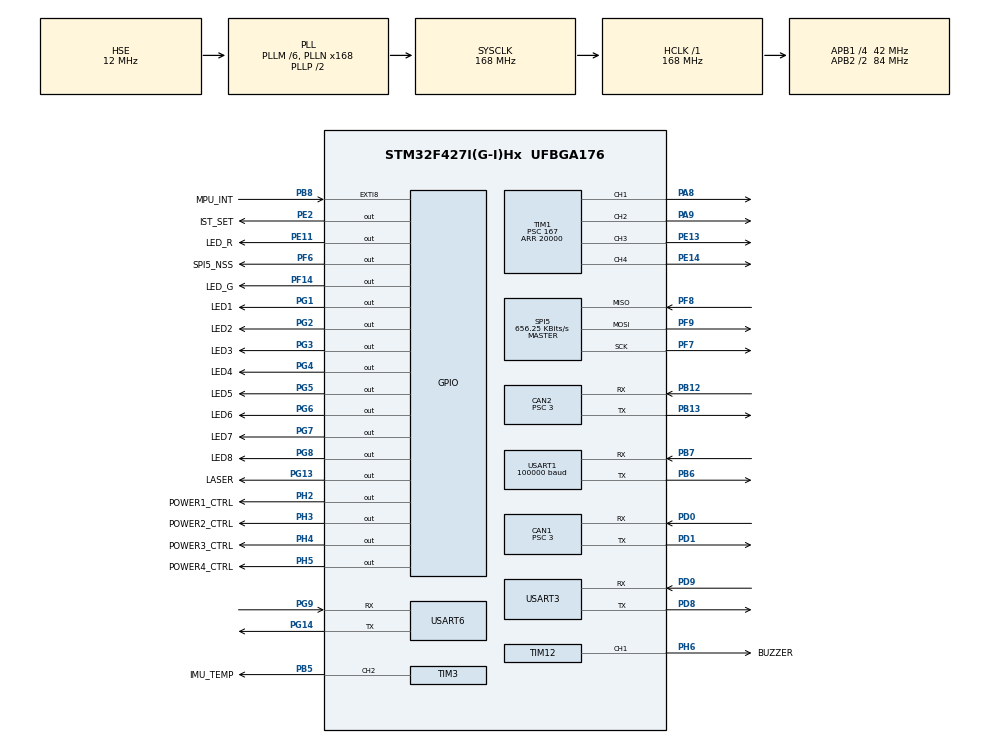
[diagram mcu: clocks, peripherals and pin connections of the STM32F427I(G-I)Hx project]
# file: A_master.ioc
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CAN1.BS1=CAN_BS1_10TQ
CAN1.BS2=CAN_BS2_3TQ
CAN1.CalculateTimeQuantum=71.42857142857143
CAN1.Prescaler=3
CAN2.BS1=CAN_BS1_10TQ
CAN2.BS2=CAN_BS2_3TQ
CAN2.CalculateTimeQuantum=71.42857142857143
CAN2.Prescaler=3
Dma.Request0=USART1_RX
Dma.Request1=SPI5_RX
Dma.Request2=USART3_RX
Dma.Request3=USART3_TX
Dma.SPI5_RX.1.Direction=DMA_PERIPH_TO_MEMORY
Dma.SPI5_RX.1.FIFOMode=DMA_FIFOMODE_DISABLE
Dma.SPI5_RX.1.Instance=DMA2_Stream3
Dma.SPI5_RX.1.MemDataAlignment=DMA_MDATAALIGN_BYTE
Dma.SPI5_RX.1.MemInc=DMA_MINC_ENABLE
Dma.SPI5_RX.1.Mode=DMA_NORMAL
Dma.SPI5_RX.1.PeriphDataAlignment=DMA_PDATAALIGN_BYTE
Dma.SPI5_RX.1.PeriphInc=DMA_PINC_DISABLE
Dma.SPI5_RX.1.Priority=DMA_PRIORITY_VERY_HIGH
Dma.USART1_RX.0.Direction=DMA_PERIPH_TO_MEMORY
Dma.USART1_RX.0.FIFOMode=DMA_FIFOMODE_DISABLE
Dma.USART1_RX.0.Instance=DMA2_Stream2
Dma.USART1_RX.0.MemDataAlignment=DMA_MDATAALIGN_BYTE
Dma.USART1_RX.0.MemInc=DMA_MINC_ENABLE
Dma.USART1_RX.0.Mode=DMA_NORMAL
Dma.USART1_RX.0.PeriphDataAlignment=DMA_PDATAALIGN_BYTE
Dma.USART1_RX.0.PeriphInc=DMA_PINC_DISABLE
Dma.USART1_RX.0.Priority=DMA_PRIORITY_LOW
Dma.USART3_RX.2.Direction=DMA_PERIPH_TO_MEMORY
Dma.USART3_RX.2.FIFOMode=DMA_FIFOMODE_DISABLE
Dma.USART3_RX.2.Instance=DMA1_Stream1
Dma.USART3_RX.2.MemDataAlignment=DMA_MDATAALIGN_BYTE
Dma.USART3_RX.2.MemInc=DMA_MINC_ENABLE
Dma.USART3_RX.2.Mode=DMA_NORMAL
Dma.USART3_RX.2.PeriphDataAlignment=DMA_PDATAALIGN_BYTE
Dma.USART3_RX.2.PeriphInc=DMA_PINC_DISABLE
Dma.USART3_RX.2.Priority=DMA_PRIORITY_LOW
Dma.USART3_TX.3.Direction=DMA_MEMORY_TO_PERIPH
Dma.USART3_TX.3.FIFOMode=DMA_FIFOMODE_DISABLE
Dma.USART3_TX.3.Instance=DMA1_Stream3
Dma.USART3_TX.3.MemDataAlignment=DMA_MDATAALIGN_BYTE
Dma.USART3_TX.3.MemInc=DMA_MINC_ENABLE
Dma.USART3_TX.3.Mode=DMA_NORMAL
Dma.USART3_TX.3.PeriphDataAlignment=DMA_PDATAALIGN_BYTE
Dma.USART3_TX.3.PeriphInc=DMA_PINC_DISABLE
Dma.USART3_TX.3.Priority=DMA_PRIORITY_LOW
FREERTOS.INCLUDE_uxTaskGetStackHighWaterMark=1
FREERTOS.INCLUDE_vTaskDelayUntil=1
FREERTOS.Tasks01=defaultTask,0,128,StartDefaultTask,Default,NULL,Dynamic,NULL,NULL
Mcu.Family=STM32F4
Mcu.Name=STM32F427I(G-I)Hx
Mcu.Package=UFBGA176
NVIC.CAN1_RX0_IRQn=true\:5\:0\:false\:false\:true\:true\:true\:true
NVIC.CAN2_RX0_IRQn=true\:5\:0\:false\:false\:true\:true\:true\:true
NVIC.DMA1_Stream1_IRQn=true\:5\:0\:false\:false\:true\:true\:false\:true
NVIC.DMA1_Stream3_IRQn=true\:5\:0\:false\:false\:true\:true\:false\:true
NVIC.DMA2_Stream2_IRQn=true\:5\:0\:false\:false\:true\:true\:false\:true
NVIC.DMA2_Stream3_IRQn=true\:5\:0\:false\:false\:true\:true\:false\:true
NVIC.PriorityGroup=NVIC_PRIORITYGROUP_4
NVIC.TIM8_TRG_COM_TIM14_IRQn=true\:0\:0\:false\:false\:true\:false\:false\:true
NVIC.TimeBase=TIM8_TRG_COM_TIM14_IRQn
NVIC.TimeBaseIP=TIM14
NVIC.USART1_IRQn=true\:5\:0\:false\:false\:true\:true\:true\:true
NVIC.USART3_IRQn=true\:5\:0\:false\:false\:true\:true\:true\:true
NVIC.USART6_IRQn=true\:5\:0\:false\:false\:true\:true\:true\:true
PA13.Mode=Serial_Wire
PA13.Signal=SYS_JTMS-SWDIO
PA14.Mode=Serial_Wire
PA14.Signal=SYS_JTCK-SWCLK
PA8.Signal=S_TIM1_CH1
PA9.Signal=S_TIM1_CH2
PB12.Mode=Slave
PB12.Signal=CAN2_RX
PB13.Mode=Slave
PB13.Signal=CAN2_TX
PB5.GPIO_Label=IMU_TEMP
PB5.Signal=S_TIM3_CH2
PB6.GPIO_PuPd=GPIO_PULLUP
PB6.Mode=Asynchronous
PB6.Signal=USART1_TX
PB7.GPIO_PuPd=GPIO_PULLUP
PB7.Mode=Asynchronous
PB7.Signal=USART1_RX
PB8.GPIO_Label=MPU_INT
PB8.GPIO_PuPd=GPIO_NOPULL
PB8.Signal=GPXTI8
PC14/OSC32_IN.Mode=LSE-External-Oscillator
PC14/OSC32_IN.Signal=RCC_OSC32_IN
PC15/OSC32_OUT.Mode=LSE-External-Oscillator
PC15/OSC32_OUT.Signal=RCC_OSC32_OUT
PD0.Mode=Master
PD0.Signal=CAN1_RX
PD1.Mode=Master
PD1.Signal=CAN1_TX
PD8.GPIO_PuPd=GPIO_PULLUP
PD8.Mode=Asynchronous
PD8.Signal=USART3_TX
PD9.GPIO_PuPd=GPIO_PULLUP
PD9.Mode=Asynchronous
PD9.Signal=USART3_RX
PE11.GPIO_Label=LED_R
PE11.Signal=GPIO_Output
PE13.Signal=S_TIM1_CH3
PE14.Signal=S_TIM1_CH4
PE2.GPIO_Label=IST_SET
PE2.GPIO_PuPd=GPIO_PULLUP
PE2.GPIO_Speed=GPIO_SPEED_FREQ_HIGH
PE2.Signal=GPIO_Output
PF14.GPIO_Label=LED_G
PF14.Signal=GPIO_Output
PF6.GPIO_Label=SPI5_NSS
PF6.GPIO_PuPd=GPIO_PULLUP
PF6.GPIO_Speed=GPIO_SPEED_FREQ_HIGH
PF6.Signal=GPIO_Output
PF7.Mode=Full_Duplex_Master
PF7.Signal=SPI5_SCK
PF8.Mode=Full_Duplex_Master
PF8.Signal=SPI5_MISO
PF9.Mode=Full_Duplex_Master
PF9.Signal=SPI5_MOSI
PG1.GPIO_Label=LED1
PG1.Signal=GPIO_Output
PG13.GPIO_Label=LASER
PG13.Signal=GPIO_Output
PG14.GPIO_PuPd=GPIO_PULLUP
PG14.Mode=Asynchronous
PG14.Signal=USART6_TX
PG2.GPIO_Label=LED2
PG2.Signal=GPIO_Output
PG3.GPIO_Label=LED3
PG3.Signal=GPIO_Output
PG4.GPIO_Label=LED4
PG4.Signal=GPIO_Output
PG5.GPIO_Label=LED5
PG5.Signal=GPIO_Output
PG6.GPIO_Label=LED6
PG6.Signal=GPIO_Output
PG7.GPIO_Label=LED7
PG7.Signal=GPIO_Output
PG8.GPIO_Label=LED8
PG8.Signal=GPIO_Output
PG9.GPIO_PuPd=GPIO_PULLUP
PG9.Mode=Asynchronous
PG9.Signal=USART6_RX
PH0/OSC_IN.Mode=HSE-External-Oscillator
PH0/OSC_IN.Signal=RCC_OSC_IN
PH1/OSC_OUT.Mode=HSE-External-Oscillator
PH1/OSC_OUT.Signal=RCC_OSC_OUT
PH2.GPIO_Label=POWER1_CTRL
PH2.GPIO_PuPd=GPIO_PULLUP
PH2.GPIO_Speed=GPIO_SPEED_FREQ_MEDIUM
PH2.Signal=GPIO_Output
PH3.GPIO_Label=POWER2_CTRL
PH3.GPIO_PuPd=GPIO_PULLUP
PH3.GPIO_Speed=GPIO_SPEED_FREQ_MEDIUM
PH3.Signal=GPIO_Output
PH4.GPIO_Label=POWER3_CTRL
PH4.GPIO_PuPd=GPIO_PULLUP
PH4.GPIO_Speed=GPIO_SPEED_FREQ_MEDIUM
PH4.Signal=GPIO_Output
PH5.GPIO_Label=POWER4_CTRL
PH5.GPIO_PuPd=GPIO_PULLUP
PH5.GPIO_Speed=GPIO_SPEED_FREQ_MEDIUM
PH5.Signal=GPIO_Output
PH6.GPIO_Label=BUZZER
PH6.GPIO_PuPd=GPIO_PULLUP
PH6.GPIO_Speed=GPIO_SPEED_FREQ_HIGH
PH6.Signal=S_TIM12_CH1
ProjectManager.HeapSize=0x200
ProjectManager.StackSize=0x400
ProjectManager.TargetToolchain=MDK-ARM V5
RCC.48MHZClocksFreq_Value=84000000
RCC.AHBFreq_Value=168000000
RCC.APB1CLKDivider=RCC_HCLK_DIV4
RCC.APB1Freq_Value=42000000
RCC.APB1TimFreq_Value=84000000
RCC.APB2CLKDivider=RCC_HCLK_DIV2
RCC.APB2Freq_Value=84000000
RCC.APB2TimFreq_Value=168000000
RCC.CortexFreq_Value=168000000
RCC.HCLKFreq_Value=168000000
RCC.HSE_VALUE=12000000
RCC.HSI_VALUE=16000000
RCC.PLLM=6
RCC.PLLN=168
RCC.PLLSourceVirtual=RCC_PLLSOURCE_HSE
RCC.SYSCLKFreq_VALUE=168000000
RCC.SYSCLKSource=RCC_SYSCLKSOURCE_PLLCLK
RCC.VCOOutputFreq_Value=336000000
SH.S_TIM12_CH1.0=TIM12_CH1,PWM Generation1 CH1
SH.S_TIM1_CH1.0=TIM1_CH1,PWM Generation1 CH1
SH.S_TIM1_CH2.0=TIM1_CH2,PWM Generation2 CH2
SH.S_TIM1_CH3.0=TIM1_CH3,PWM Generation3 CH3
SH.S_TIM1_CH4.0=TIM1_CH4,PWM Generation4 CH4
SH.S_TIM3_CH2.0=TIM3_CH2,PWM Generation2 CH2
SPI5.BaudRatePrescaler=SPI_BAUDRATEPRESCALER_128
SPI5.CalculateBaudRate=656.25 KBits/s
SPI5.Direction=SPI_DIRECTION_2LINES
SPI5.Mode=SPI_MODE_MASTER
SPI5.VirtualType=VM_MASTER
TIM1.Channel-PWM\ Generation1\ CH1=TIM_CHANNEL_1
TIM1.Channel-PWM\ Generation2\ CH2=TIM_CHANNEL_2
TIM1.Channel-PWM\ Generation3\ CH3=TIM_CHANNEL_3
TIM1.Channel-PWM\ Generation4\ CH4=TIM_CHANNEL_4
TIM1.OCMode_PWM-PWM\ Generation4\ CH4=TIM_OCMODE_PWM1
TIM1.Period=20000
TIM1.Prescaler=167
TIM1.Pulse-PWM\ Generation1\ CH1=2000
TIM1.Pulse-PWM\ Generation2\ CH2=2000
TIM1.Pulse-PWM\ Generation3\ CH3=2000
TIM1.Pulse-PWM\ Generation4\ CH4=2000
TIM12.Channel-PWM\ Generation1\ CH1=TIM_CHANNEL_1
TIM12.Period=2500-1
TIM12.Prescaler=84-1
TIM3.Channel-PWM\ Generation2\ CH2=TIM_CHANNEL_2
TIM3.Prescaler=84-1
USART1.BaudRate=100000
USART1.VirtualMode=VM_ASYNC
USART3.VirtualMode=VM_ASYNC
USART6.VirtualMode=VM_ASYNC
VP_FREERTOS_VS_CMSIS_V1.Mode=CMSIS_V1
VP_SYS_VS_tim14.Mode=TIM14
VP_TIM12_VS_ClockSourceINT.Mode=Internal
VP_TIM1_VS_ClockSourceINT.Mode=Internal
VP_TIM3_VS_ClockSourceINT.Mode=Internal
board=custom

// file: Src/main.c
/* USER CODE BEGIN Header */
/**
  ******************************************************************************
  * @file           : main.c
  * @brief          : Main program body
  ******************************************************************************
  * @attention
  *
  * <h2><center>&copy; Copyright (c) 2020 STMicroelectronics.
  * All rights reserved.</center></h2>
  *
  * This software component is licensed by ST under Ultimate Liberty license
  * SLA0044, the "License"; You may not use this file except in compliance with
  * the License. You may obtain a copy of the License at:
  *                             www.st.com/SLA0044
  *
  ******************************************************************************
  */
/* USER CODE END Header */

#include "main.h"
#include "cmsis_os.h"
#include "can.h"
#include "dma.h"
#include "spi.h"
#include "tim.h"
#include "usart.h"
#include "gpio.h"

/* USER CODE BEGIN Includes */
#include "can_user.h"
/* USER CODE END Includes */

void SystemClock_Config(void);
void MX_FREERTOS_Init(void);

int main(void)
{

  /* MCU Configuration--------------------------------------------------------*/

  /* Reset of all peripherals, Initializes the Flash interface and the Systick. */
		HAL_Init();

  /* Configure the system clock */
  SystemClock_Config();

  /* Initialize all configured peripherals */
  MX_GPIO_Init();
  MX_DMA_Init();
  MX_CAN1_Init();
  MX_CAN2_Init();
  MX_SPI5_Init();
  MX_TIM1_Init();
  MX_TIM3_Init();
  MX_TIM12_Init();
  MX_USART1_UART_Init();
  MX_USART3_UART_Init();
  MX_USART6_UART_Init();
  /* USER CODE BEGIN 2 */
  vApp_User_CAN_Configuration();
  /* USER CODE END 2 */

  /* Call init function for freertos objects (in freertos.c) */
  MX_FREERTOS_Init();

  /* Start scheduler */
  osKernelStart();

  /* We should never get here as control is now taken by the scheduler */

  /* Infinite loop */
  while (1)
  {

  }
}

void SystemClock_Config(void)
{
  RCC_OscInitTypeDef RCC_OscInitStruct = {0};
  RCC_ClkInitTypeDef RCC_ClkInitStruct = {0};

  /** Configure the main internal regulator output voltage
  */
  __HAL_RCC_PWR_CLK_ENABLE();
  __HAL_PWR_VOLTAGESCALING_CONFIG(PWR_REGULATOR_VOLTAGE_SCALE1);
  /** Initializes the CPU, AHB and APB busses clocks
  */
  RCC_OscInitStruct.OscillatorType = RCC_OSCILLATORTYPE_HSE;
  RCC_OscInitStruct.HSEState = RCC_HSE_ON;
  RCC_OscInitStruct.PLL.PLLState = RCC_PLL_ON;
  RCC_OscInitStruct.PLL.PLLSource = RCC_PLLSOURCE_HSE;
  RCC_OscInitStruct.PLL.PLLM = 6;
  RCC_OscInitStruct.PLL.PLLN = 168;
  RCC_OscInitStruct.PLL.PLLP = RCC_PLLP_DIV2;
  RCC_OscInitStruct.PLL.PLLQ = 4;
  if (HAL_RCC_OscConfig(&RCC_OscInitStruct) != HAL_OK)
  {
    Error_Handler();
  }
  /** Initializes the CPU, AHB and APB busses clocks
  */
  RCC_ClkInitStruct.ClockType = RCC_CLOCKTYPE_HCLK|RCC_CLOCKTYPE_SYSCLK
                              |RCC_CLOCKTYPE_PCLK1|RCC_CLOCKTYPE_PCLK2;
  RCC_ClkInitStruct.SYSCLKSource = RCC_SYSCLKSOURCE_PLLCLK;
  RCC_ClkInitStruct.AHBCLKDivider = RCC_SYSCLK_DIV1;
  RCC_ClkInitStruct.APB1CLKDivider = RCC_HCLK_DIV4;
  RCC_ClkInitStruct.APB2CLKDivider = RCC_HCLK_DIV2;

  if (HAL_RCC_ClockConfig(&RCC_ClkInitStruct, FLASH_LATENCY_5) != HAL_OK)
  {
    Error_Handler();
  }
}

void HAL_TIM_PeriodElapsedCallback(TIM_HandleTypeDef *htim)
{
  if (htim->Instance == TIM14) {
    HAL_IncTick();
  }
}

void Error_Handler(void)
{
}

/************************ (C) COPYRIGHT STMicroelectronics *****END OF FILE****/

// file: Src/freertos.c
/* USER CODE BEGIN Header */
/**
  ******************************************************************************
  * File Name          : freertos.c
  * Description        : Code for freertos applications
  ******************************************************************************
  * @attention
  *
  * <h2><center>&copy; Copyright (c) 2020 STMicroelectronics.
  * All rights reserved.</center></h2>
  *
  * This software component is licensed by ST under Ultimate Liberty license
  * SLA0044, the "License"; You may not use this file except in compliance with
  * the License. You may obtain a copy of the License at:
  *                             www.st.com/SLA0044
  *
  ******************************************************************************
  */
/* USER CODE END Header */

#include "FreeRTOS.h"
#include "task.h"
#include "main.h"
#include "cmsis_os.h"

/* USER CODE BEGIN Includes */

#include "can_user.h"
#include "chassis_task.h"
/* USER CODE END Includes */

osThreadId defaultTaskHandle;
osThreadId chassisTaskHandle;

void StartDefaultTask(void const * argument);

void MX_FREERTOS_Init(void); /* (MISRA C 2004 rule 8.1) */

/* GetIdleTaskMemory prototype (linked to static allocation support) */
void vApplicationGetIdleTaskMemory( StaticTask_t **ppxIdleTaskTCBBuffer, StackType_t **ppxIdleTaskStackBuffer, uint32_t *pulIdleTaskStackSize );

/* USER CODE BEGIN GET_IDLE_TASK_MEMORY */
static StaticTask_t xIdleTaskTCBBuffer;
static StackType_t xIdleStack[configMINIMAL_STACK_SIZE];

void vApplicationGetIdleTaskMemory( StaticTask_t **ppxIdleTaskTCBBuffer, StackType_t **ppxIdleTaskStackBuffer, uint32_t *pulIdleTaskStackSize )
{
  *ppxIdleTaskTCBBuffer = &xIdleTaskTCBBuffer;
  *ppxIdleTaskStackBuffer = &xIdleStack[0];
  *pulIdleTaskStackSize = configMINIMAL_STACK_SIZE;
  /* place for user code */
}
/* USER CODE END GET_IDLE_TASK_MEMORY */

void MX_FREERTOS_Init(void) {

  /* Create the thread(s) */
  /* definition and creation of defaultTask */
  osThreadDef(defaultTask, StartDefaultTask, osPriorityNormal, 0, 128);
  defaultTaskHandle = osThreadCreate(osThread(defaultTask), NULL);

  /* USER CODE BEGIN RTOS_THREADS */
  /* add threads, ... */
	osThreadDef(chassisTask, chassis_task, osPriorityNormal, 0, 512);
  chassisTaskHandle = osThreadCreate(osThread(chassisTask), NULL);
  /* USER CODE END RTOS_THREADS */

}

void StartDefaultTask(void const * argument)
{
  for(;;)
  {
    osDelay(1);
  }
}

/************************ (C) COPYRIGHT STMicroelectronics *****END OF FILE****/
